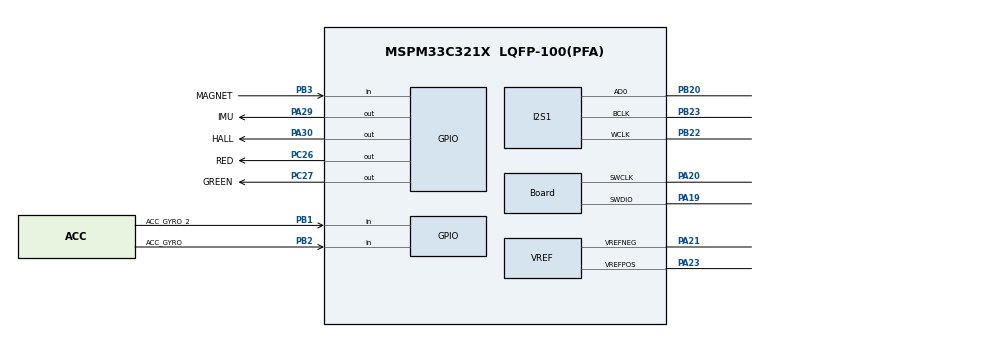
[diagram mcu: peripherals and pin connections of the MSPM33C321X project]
/**
 *
 * @cliArgs --device "MSPM33C321X" --part "Default" --package "LQFP-100(PFA)" --product "mspm33_sdk@1.03.00.01"
 * @versions {"tool":"1.28.0+4696"}
 */
// @cliArgs --board /ti/boards/LP_MSPM33C321A --rtos nortos

/**
 * Import the modules used in this configuration.
 */
const Board  = scripting.addModule("/ti/driverlib/Board");
const GPIO   = scripting.addModule("/ti/driverlib/GPIO", {}, false);
const GPIO1  = GPIO.addInstance();
const GPIO2  = GPIO.addInstance();
const GPIO3  = GPIO.addInstance();
const HSADC  = scripting.addModule("/ti/driverlib/HSADC", {}, false);
const HSADC1 = HSADC.addInstance();
const I2S    = scripting.addModule("/ti/driverlib/I2S", {}, false);
const I2S1   = I2S.addInstance();
const SYSCTL = scripting.addModule("/ti/driverlib/SYSCTL");
const TIMER  = scripting.addModule("/ti/driverlib/TIMER", {}, false);
const TIMER1 = TIMER.addInstance();
const VREF   = scripting.addModule("/ti/driverlib/VREF");

/**
 * Write custom configuration values to the imported modules.
 */
Board.genPeriphPinFile            = true;
Board.peripheral.$assign          = "DEBUGSS";
Board.peripheral.swclkPin.$assign = "PA20";
Board.peripheral.swdioPin.$assign = "PA19";
Board.genFileMod.$name            = "ti_driverlib_BoardPins0";

GPIO1.$name                         = "LED";
GPIO1.associatedPins.create(2);
GPIO1.associatedPins[0].$name       = "RED";
GPIO1.associatedPins[0].pin.$assign = "PC26";
GPIO1.associatedPins[1].$name       = "GREEN";
GPIO1.associatedPins[1].pin.$assign = "PC27";

GPIO2.$name                         = "SENSOR_INTR";
GPIO2.associatedPins.create(3);
GPIO2.associatedPins[0].direction   = "INPUT";
GPIO2.associatedPins[0].polarity    = "FALL";
GPIO2.associatedPins[0].interruptEn = true;
GPIO2.associatedPins[0].$name       = "ACC_GYRO";
GPIO2.associatedPins[0].pin.$assign = "PB2";
GPIO2.associatedPins[1].direction   = "INPUT";
GPIO2.associatedPins[1].polarity    = "FALL";
GPIO2.associatedPins[1].interruptEn = true;
GPIO2.associatedPins[1].$name       = "MAGNET";
GPIO2.associatedPins[1].pin.$assign = "PB3";
GPIO2.associatedPins[2].direction   = "INPUT";
GPIO2.associatedPins[2].polarity    = "FALL";
GPIO2.associatedPins[2].interruptEn = true;
GPIO2.associatedPins[2].$name       = "ACC_GYRO_2";
GPIO2.associatedPins[2].pin.$assign = "PB1";

GPIO3.$name                          = "SPI_CS";
GPIO3.associatedPins.create(2);
GPIO3.associatedPins[0].$name        = "IMU";
GPIO3.associatedPins[0].initialValue = "SET";
GPIO3.associatedPins[0].pin.$assign  = "PA29";
GPIO3.associatedPins[1].$name        = "HALL";
GPIO3.associatedPins[1].initialValue = "SET";
GPIO3.associatedPins[1].pin.$assign  = "PA30";

HSADC1.$name                             = "HSADC0";
HSADC1.enabledSOCs                       = ["ADC_SOC_NUMBER0"];
HSADC1.interruptPulseMode                = "ADC_PULSE_END_OF_CONV";
HSADC1.seq1Enable                        = true;
HSADC1.enableDMAInterrupt1               = true;
HSADC1.enableDMAInterrupt1ContinuousMode = true;
HSADC1.enabledInts                       = ["ADC_INT_NUMBER_1"];
HSADC1.enableInterrupt1                  = true;
HSADC1.enableInterrupt1ContinuousMode    = true;
HSADC1.enabledSEQs                       = ["ADC_SEQ_NUMBER1"];
HSADC1.ADCsubscriber1Channel             = 1;
HSADC1.seq1TriggerSel                    = "ADC_TRIGGER_GEN_SUB_0";
HSADC1.adcEventInterrupt                 = true;
HSADC1.soc0Channel                       = "ADC_CH_ADCIN_10";
HSADC1.seq1SampleWindow                  = 64;
HSADC1.ppb1AccumulationLimit             = "ADC_OVERSAMPLING_LIMIT_8";
HSADC1.ppb1Rightshift                    = 3;
HSADC1.ppb1CompSource                    = "ADC_PPB_COMPSOURCE_SUM";
HSADC1.peripheral.$assign                = "ADC0";
HSADC1.peripheral.adcPin10.$assign       = "PA18";

I2S1.$name                      = "I2S_0";
I2S1.phase                      = "DUAL";
I2S1.sampleWordLength           = 32;
I2S1.dataDelay                  = "ONE";
I2S1.memoryAccessLength         = "32";
I2S1.wordBaudClockSource        = "INTERNAL";
I2S1.wclkPhase                  = "DUAL";
I2S1.wclkDivider                = 32;
I2S1.bclkDivider                = 8;
I2S1.dataPin0Enable             = true;
I2S1.peripheral.$assign         = "I2S1";
I2S1.peripheral.AD0Pin.$assign  = "PB20";
I2S1.peripheral.BCLKPin.$assign = "PB23";
I2S1.peripheral.WCLKPin.$assign = "PB22";

SYSCTL.forceDefaultClkConfig = true;
SYSCTL.SYSPLL_CLK2XDiv       = 1;
SYSCTL.SYSPLL_CLK0En         = true;
SYSCTL.SYSPLL_Pdiv           = 1;
SYSCTL.MCLKSource            = "HSCLK";
SYSCTL.validateClkStatus     = true;
SYSCTL.SYSPLL_CLK1En         = true;
SYSCTL.SYSPLL_CLK2XEn        = true;
SYSCTL.peripheral.$assign    = "SYSCTL";
SYSCTL.I2SCLKSource       = "SYSOSC";

TIMER1.$name                       = "TIMER_0";
TIMER1.timerClkPrescale            = 256;
TIMER1.timerClkDiv                 = 8;
TIMER1.event1PublisherChannel      = 1;
TIMER1.event1ControllerInterruptEn = ["ZERO_EVENT"];
TIMER1.timerMode                   = "PERIODIC_UP";
TIMER1.timerPeriod                 = "30.3 ms";
TIMER1.peripheral.$assign          = "TIMA0_0";

VREF.basicMode                     = "DL_VREF_ENABLE_DISABLE";
VREF.basicVrefPins                 = "VREF+-";
VREF.basicExtVolt                  = 3.3;
VREF.vrefPosPinConfig.$name        = "ti_driverlib_gpio_GPIOPinGeneric52";
VREF.peripheral.$assign            = "VREF";
VREF.peripheral.vrefPosPin.$assign = "PA23";
VREF.peripheral.vrefNegPin.$assign = "PA21";
VREF.vrefNegPinConfig.$name        = "ti_driverlib_gpio_GPIOPinGeneric53";

const ProjectConfig              = scripting.addModule("/ti/project_config/ProjectConfig", {}, false);
ProjectConfig.migrationCondition = true;
ProjectConfig.genLibCMSIS        = true;
